# V32F20x_CM33 register map
File version: 1.0.3
CPU: CM33 r0p4, little endian, MPU, FPU, DSP, 3 interrupt priority bits, 8 SAU regions
Registers are 32-bit, read-write, reset 0x0 unless marked. A register's access mark holds for its fields unless they carry their own. Offsets are from the block's base; [hi:lo] are bit positions; 'fields as' and 'values as' point back to an identical list.

## RTC — RTC Peripheral Interface
Base 0x40103000
Same registers: SEC_RTC 0x50103000
0x00 SEC — RTC calendar time second register.
  [6:0] SEC — RTC calendar time second in BCD format.
0x04 MIN — RTC calendar time minute register.
  [6:0] MIN — RTC calendar time minute in BCD format.
0x08 HOUR — RTC calendar time hour register.
  [5:0] HOUR — RTC calendar time hour in BCD format.
0x0C DAY — RTC calendar time day register.
  [5:0] DAY — RTC calendar time day in BCD format.
0x10 WEEK — RTC calendar time week register.
  [2:0] WEEK — RTC calendar time week in BCD format.
0x14 MON — RTC calendar time month register.
  [4:0] MON — RTC calendar time month in BCD format.
0x18 YEAR — RTC calendar time year register.
  [7:0] YEAR — RTC calendar time year in BCD format.
0x1C TIME — RTC accurate subsecond time register.
  [21:0] TIME — RTC accurate subsecond time in BCD format.
0x20 PLLDIVAC ro — RTC PLL divider value after auto calibration register
  [25:0] PLLDIVAC — RTC PLL divider value after auto calibration compensation
0x30 CAL reset 0x1 — RTC calibration register.
  [13:0] CAL — RTC 32768 calibration the RTC engine will do calibration for every 30 seconds the internal counter will count 32768 times during 1 29 second
0x38 CTRL — RTC control register.
  [1] TIMEEN — RTC sub-second counter enable
0x44 PWD — RTC_CE access protection register.
  [0] PWDEN — This field is used to protect the RTC_CE port access
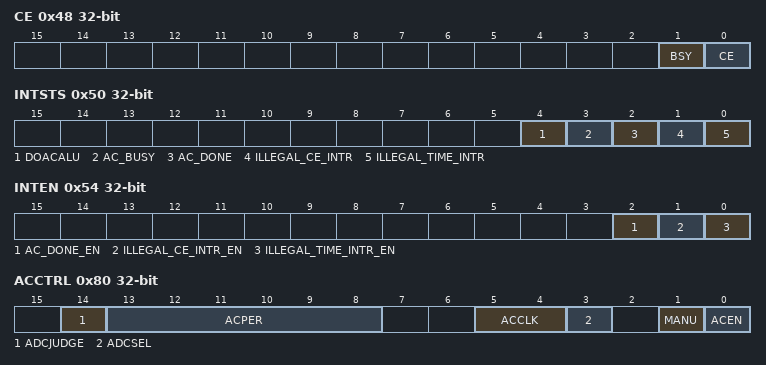
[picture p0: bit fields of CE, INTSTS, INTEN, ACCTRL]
0x48 CE — RTC time registers access protection register.
  [1] BSY — This flag indicates the RTC update procedure or RTC read procedure is ongoing
  [0] CE — This field is used to unlock the access to RTC calendar time registers
0x4C LOAD — RTC calendar time load register.
0x50 INTSTS — RTC interrupt status register.
  [4] DOACALU — When the current data needs to do auto calibration this bit will be asserted interrupt will not be asserted to CPU
  [3] AC_BUSY — Auto-calibration busy flag.
  [2] AC_DONE — Calibration done interrupt.
  [1] ILLEGAL_CE_INTR — Illegal write to CE register interrupt.
  [0] ILLEGAL_TIME_INTR — Illegal time checking interrupt.
0x54 INTEN — RTC interrupt enable register.
  [2] AC_DONE_EN — Auto calibration interrupt enable.
  [1] ILLEGAL_CE_INTR_EN — Illegal write to CE register interrupt enable
  [0] ILLEGAL_TIME_INTR_EN — Illegal time checking interrupt enable.
0x58 WKUSEC — RTC only wakeup time second register .
  [6:0] WKUSEC — This field is used to specify the RTCOnly wakeup time second
0x5C WKUMIN — RTC only wakeup time minute register.
  [6:0] WKUMIN — This field is used to specifythe RTCOnly wakeup time minute
0x60 WKUHOUR — RTC only wakeup time hour register.
  [5:0] WKUHOUR — This field is used to specify the RTCOnly wakeup time hour
0x64 WKUDAY — RTC only wakeup time day register.
  [5:0] WKUDAY — This field is used to specify the RTCOnly wakeup time day
0x68 WKUMONTH — RTC only wakeup time month register.
  [4:0] WKUMONTH — This field is used to specify the RTCOnly wakeup time month
0x6C WKUYEAR — RTC only wakeup time year register.
  [7:0] WKUYEAR — This field is used to specify the RTCOnly wakeup time year
0x80 ACCTRL — RTC calibration control register.
  [14] ADCJUDGE — ADC data judge enable
  [13:8] ACPER — Auto trigger period control the actual period is controlled by ACPER 1 ACCLK
  [5:4] ACCLK — Auto-trigger clock source selection
  [3] ADCSEL — ADC source select
  [1] MANU — Auto-calibration manual trigger function
  [0] ACEN — Auto-calibration enable
0x84 ACTI reset 0x1800 — Auto-calibration center temperature control register
  [13:0] ACTI — Auto-calibration Ti control.
0x88 ACF200 reset 0x640000 — Auto-calibration F200 control register.
  [25:0] F200 — Auto-calibration F200 control.
0x8C ACADCW — Auto-calibration manual ADC value control register
  [11:0] ACADCW — This field is used to store the manual ADC value which is used for the calculation for temperature
0x90 ACP0 — Auto-calibration P0 register.
  [15:0] ACP0 — ACP0 is parameter p0 used for auto calibration
0x94 ACP1 — Auto-calibration P1 register.
  [15:0] ACP1 — ACP1 is parameter P1 used for auto calibration
0x98 ACP2 — Auto-calibration P2 register.
  [31:0] ACP2 — ACP2 is parameter P2 used for auto calibration
0x9C ACP3 — Auto-calibration P3 register.
  [15:0] ACP3 — ACP3 is a 16 bit signed value and ACP3 is the K coefficient of the crystal for the current temperature
0xA0 ACP4 — Auto-calibration P4 register.
  [15:0] ACP4 — ACP4 is a 16 bit signed value and it stores the crystal deviation in normal temperature
0xA4 ACP5 — Auto-calibration P5 register.
  [15:0] ACP5 — ACP5 is a 16 bit signed value and it is used to generate one second pulse
0xA8 ACP6 — Auto-calibration P6 register.
  [15:0] ACP6 — ACP6 is a 16 bit signed value and it is used to generate one second pulse output by PLL clock
0xAC ACP7 — Auto-calibration P7 register.
  [15:0] ACP7 — ACP7 is a 16 bit signed value and it is used for frequency calibration
0xB0 ACK1 — Auto-calibration K1 register.
  [15:0] ACK1 — ACK1 is 16 bit signed and used for auto calibration
0xB4 ACK2 — Auto-calibration K2 register.
  [15:0] ACK2 — ACK2 is 16 bit signed and used for auto calibration
0xB8 ACK3 — Auto-calibration K3 register.
  [31:0] ACK3 — ACK3 is 16 bit signed and used for auto calibration
0xBC ACK4 — Auto-calibration K4 register.
  [15:0] ACK4 — ACK4 is 16 bit signed and used for auto calibration
0xC0 ACK5 — Auto-calibration K5 register.
  [15:0] ACK5 — ACK5 is 16 bit signed and used for auto calibration
0xC4 ACTEMP ro — Auto-calibration calculated temperature register.
  [15:0] TEMP — This field is used to store the calculated result of current temperature
0xC8 ACPPM ro — Auto-calibration calculated PPM register.
  [15:0] PPM — This field is used to store the calculated PPM part per million
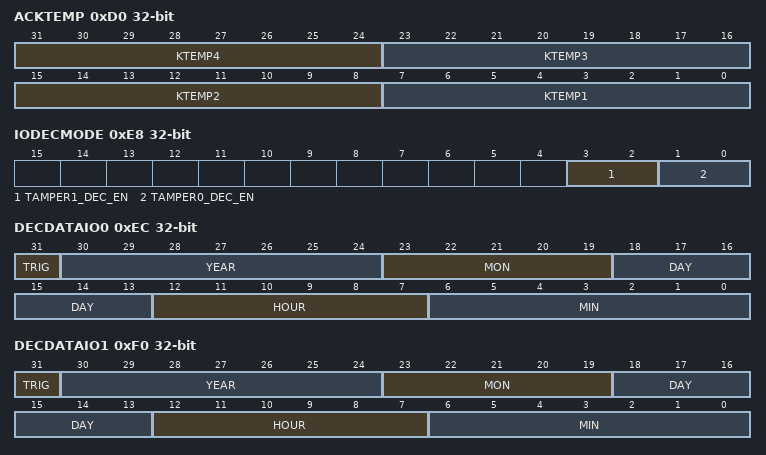
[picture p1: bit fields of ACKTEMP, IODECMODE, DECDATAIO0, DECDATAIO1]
0xD0 ACKTEMP — Auto-calibration temperature section control register
  [31:24] KTEMP4 — This field is used to control the section 3 temperature
  [23:16] KTEMP3 — This field is used to control the section 3 temperature
  [15:8] KTEMP2 — This field is used to control the section 2 temperature
  [7:0] KTEMP1 — This field is used to control the section 1 temperature
0xE8 IODECMODE — RTC uncovering detection mode register.
  [3:2] TAMPER1_DEC_EN — IOI8 used as TAMPER1 detecting.
  [1:0] TAMPER0_DEC_EN — IOC13 used as TAMPER0 detecting.
0xEC DECDATAIO0 ro — RTC uncovering detection FIFO 0 register.
  [31] TRIG — This bit indicates the time is triggered by rising edge or falling edge
  [30:24] YEAR — Year data (BCD).
  [23:19] MON — Month data (BCD).
  [18:13] DAY — Day data (BCD).
  [12:7] HOUR — Hour data (BCD).
  [6:0] MIN — Minute data (BCD).
0xF0 DECDATAIO1 ro — RTC uncovering detection FIFO 1 register.
  fields as DECDATAIO0
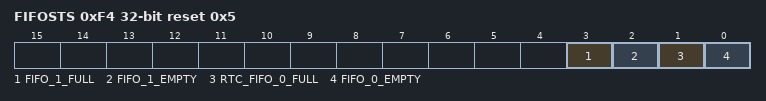
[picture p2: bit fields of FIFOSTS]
0xF4 FIFOSTS ro reset 0x5 — RTC uncovering detection FIFO status register.
  [3] FIFO_1_FULL — The field is used to indicate the full status of FIFO 1 which stores the data of IOI8
  [2] FIFO_1_EMPTY — The field is used to indicate the empty status of FIFO 1 which stores the data of IOI8
  [1] RTC_FIFO_0_FULL — The field is used to indicate the full status of FIFO 0 which stores the data of IOC13
  [0] FIFO_0_EMPTY — The field is used to indicate the empty status of FIFO 0 which stores the data of IOC13
